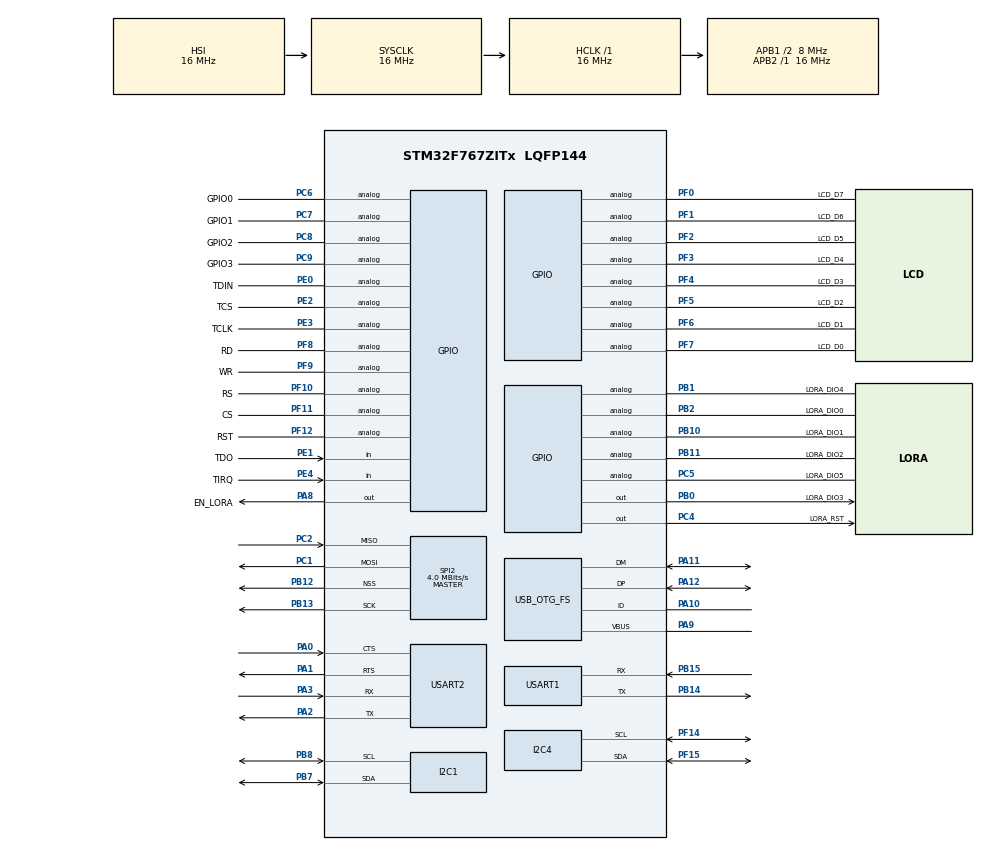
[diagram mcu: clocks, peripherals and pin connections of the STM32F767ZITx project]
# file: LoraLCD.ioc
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SPI2.VirtualType=VM_MASTER
PC6.GPIO_Label=GPIO0
PB13.Signal=SPI2_SCK
PF6.GPIO_Label=LCD_D1
PF7.Signal=GPIO_Analog
I2C4.Timing=0x2000090E
RCC.APB2TimFreq_Value=16000000
PC7.Signal=GPIO_Analog
PH1/OSC_OUT.Signal=RCC_OSC_OUT
PE1.Signal=GPIO_Input
PF10.GPIO_Label=RS
PB2.Signal=GPIO_Analog
PF1.GPIO_Label=LCD_D6
PF12.GPIO_Label=RST
PC4.GPIO_Label=LORA_RST
PB14.Mode=Asynchronous
PB1.GPIO_Label=LORA_DIO4
PE4.GPIO_Label=TIRQ
SPI2.CalculateBaudRate=4.0 MBits/s
PE2.Signal=GPIO_Analog
PA8.Signal=GPIO_Output
PF3.Signal=GPIO_Analog
Mcu.Package=LQFP144
PB1.Signal=GPIO_Analog
SPI2.Mode=SPI_MODE_MASTER
PA10.Signal=USB_OTG_FS_ID
PF14.Signal=I2C4_SCL
RCC.APB1TimFreq_Value=16000000
PB13.Mode=Full_Duplex_Master
PC2.Signal=SPI2_MISO
PC6.Signal=GPIO_Analog
PB11.GPIO_Label=LORA_DIO2
RCC.APB1CLKDivider=RCC_HCLK_DIV2
PF8.GPIO_Label=RD
PA3.Mode=Asynchronous
PA8.GPIO_Label=EN_LORA
PA9.Signal=USB_OTG_FS_VBUS
I2C1.Timing=0x2000090E
PA0/WKUP.Mode=CTS_RTS
PB10.Signal=GPIO_Analog
PB14.Signal=USART1_TX
PE1.GPIO_Label=TDO
PA1.Mode=CTS_RTS
RCC.PRESCALERUSB=RCC_USBCLKSOURCE_PLL_DIV1_5
PF4.GPIO_Label=LCD_D3
PC7.GPIO_Label=GPIO1
PA11.Signal=USB_OTG_FS_DM
ProjectManager.HeapSize=0x200
PF9.Signal=GPIO_Analog
NVIC.PriorityGroup=NVIC_PRIORITYGROUP_4
PF0.GPIO_Label=LCD_D7
PB8.Mode=I2C
PE3.Signal=GPIO_Analog
PC15/OSC32_OUT.Signal=RCC_OSC32_OUT
PF4.Signal=GPIO_Analog
PB0.Signal=GPIO_Output
PC1.Signal=SPI2_MOSI
PC1.Mode=Full_Duplex_Master
Mcu.Family=STM32F7
SPI2.VirtualNSS=VM_NSSHARD
RCC.CortexFreq_Value=16000000
RCC.SYSCLKSourceVirtual=RCC_SYSCLKSOURCE_PLLCLK
PA11.Mode=OTG/Dual_Role_Device
PA0/WKUP.Signal=USART2_CTS
PC14/OSC32_IN.Mode=LSE-External-Oscillator
PB0.GPIO_Label=LORA_DIO3
PB11.Signal=GPIO_Analog
PB15.Signal=USART1_RX
ProjectManager.StackSize=0x400
PA12.Signal=USB_OTG_FS_DP
PH0/OSC_IN.Mode=HSE-External-Oscillator
RCC.HCLKFreq_Value=16000000
PF11.GPIO_Label=CS
PF12.Signal=GPIO_Analog
RCC.AHBFreq_Value=16000000
RCC.HSE_VALUE=16000000
USART2.VirtualMode-Asynchronous=VM_ASYNC
RCC.PLLMUL=RCC_PLL_MUL9
PF7.GPIO_Label=LCD_D0
PF11.Signal=GPIO_Analog
PB7.Signal=I2C1_SDA
PE4.Signal=GPIO_Input
PH1/OSC_OUT.Mode=HSE-External-Oscillator
PF15.Mode=I2C
PB12.Mode=NSS_Signal_Hard_Output
PC14/OSC32_IN.Signal=RCC_OSC32_IN
PF5.GPIO_Label=LCD_D2
PF8.Signal=GPIO_Analog
PE0.GPIO_Label=TDIN
PF5.Signal=GPIO_Analog
SPI2.Direction=SPI_DIRECTION_2LINES
PF0.Signal=GPIO_Analog
PC5.Signal=GPIO_Analog
PF3.GPIO_Label=LCD_D4
PE2.GPIO_Label=TCS
PA3.Signal=USART2_RX
PA10.Mode=OTG/Dual_Role_Device
PC9.GPIO_Label=GPIO3
PC8.Signal=GPIO_Analog
PC4.Signal=GPIO_Output
PC2.Mode=Full_Duplex_Master
PC8.GPIO_Label=GPIO2
USART1.VirtualMode-Asynchronous=VM_ASYNC
PA9.Mode=Activate_VBUS
PF6.Signal=GPIO_Analog
ProjectManager.TargetToolchain=Makefile
PB10.GPIO_Label=LORA_DIO1
PF2.Signal=GPIO_Analog
RCC.USBFreq_Value=48000000
PF9.GPIO_Label=WR
PA1.Signal=USART2_RTS
board=NUCLEO-F767ZI
RCC.VCOOutputFreq_Value=192000000
PB15.Mode=Asynchronous
PH0/OSC_IN.Signal=RCC_OSC_IN
RCC.APB2Freq_Value=16000000
PF10.Signal=GPIO_Analog
PF14.Mode=I2C
PF15.Signal=I2C4_SDA
PF1.Signal=GPIO_Analog
Mcu.Name=STM32F767ZITx
PE0.Signal=GPIO_Analog
PA2.Signal=USART2_TX
RCC.48MHZClocksFreq_Value=24000000
RCC.SYSCLKFreq_VALUE=16000000
PA12.Mode=OTG/Dual_Role_Device
PC5.GPIO_Label=LORA_DIO5
PC15/OSC32_OUT.Mode=LSE-External-Oscillator
PB7.Mode=I2C
PB2.GPIO_Label=LORA_DIO0
RCC.HSI_VALUE=16000000
RCC.PLLQ=4
RCC.PLLM=8
RCC.PLLN=96
PA2.Mode=Asynchronous
PB8.Signal=I2C1_SCL
PE3.GPIO_Label=TCLK
PC9.Signal=GPIO_Analog
RCC.APB1Freq_Value=8000000
PB12.Signal=SPI2_NSS
PF2.GPIO_Label=LCD_D5

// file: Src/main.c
/* USER CODE BEGIN Header */
/**
 ******************************************************************************
 * @file           : main.c
 * @brief          : Main program body
 ******************************************************************************
 * @attention
 *
 * <h2><center>&copy; Copyright (c) 2020 STMicroelectronics.
 * All rights reserved.</center></h2>
 *
 * This software component is licensed by ST under BSD 3-Clause license,
 * the "License"; You may not use this file except in compliance with the
 * License. You may obtain a copy of the License at:
 *                        opensource.org/licenses/BSD-3-Clause
 *
 ******************************************************************************
 */
/* USER CODE END Header */

#include "main.h"

/* USER CODE BEGIN Includes */
#include "LCDConfigure.h"

/* USER CODE END Includes */

I2C_HandleTypeDef hi2c1;
I2C_HandleTypeDef hi2c4;

SPI_HandleTypeDef hspi2;

UART_HandleTypeDef huart1;
UART_HandleTypeDef huart2;

/* USER CODE BEGIN PV */
struct TABLE *ttable;
COLOR dotColor = (COLOR) BLUE;

/* USER CODE END PV */

void SystemClock_Config(void);
static void MX_GPIO_Init(void);
static void MX_I2C1_Init(void);
static void MX_I2C4_Init(void);
static void MX_SPI2_Init(void);
static void MX_USART1_UART_Init(void);
static void MX_USART2_UART_Init(void);
static void MX_USB_OTG_FS_USB_Init(void);

int main(void) {

	/* MCU Configuration--------------------------------------------------------*/

	/* Reset of all peripherals, Initializes the Flash interface and the Systick. */
	HAL_Init();

	/* Configure the system clock */
	SystemClock_Config();

	/* Initialize all configured peripherals */
	MX_GPIO_Init();
	MX_I2C1_Init();
	MX_I2C4_Init();
	MX_SPI2_Init();
	MX_USART1_UART_Init();
	MX_USART2_UART_Init();
	MX_USB_OTG_FS_USB_Init();
	/* USER CODE BEGIN 2 */
	ConfigureLCD7Inch();

	COLOR background = (COLOR) WHITE;
	write_screen_color(background);

	/* USER CODE END 2 */

	/* Infinite loop */
	while (1) {

	}
}

void SystemClock_Config(void) {
	RCC_OscInitTypeDef RCC_OscInitStruct = { 0 };
	RCC_ClkInitTypeDef RCC_ClkInitStruct = { 0 };
	RCC_PeriphCLKInitTypeDef PeriphClkInitStruct = { 0 };

	/** Configure LSE Drive Capability
	 */
	HAL_PWR_EnableBkUpAccess();
	/** Configure the main internal regulator output voltage
	 */
	__HAL_RCC_PWR_CLK_ENABLE();
	__HAL_PWR_VOLTAGESCALING_CONFIG(PWR_REGULATOR_VOLTAGE_SCALE3);
	/** Initializes the CPU, AHB and APB busses clocks
	 */
	RCC_OscInitStruct.OscillatorType = RCC_OSCILLATORTYPE_HSI
			| RCC_OSCILLATORTYPE_HSE;
	RCC_OscInitStruct.HSEState = RCC_HSE_ON;
	RCC_OscInitStruct.HSIState = RCC_HSI_ON;
	RCC_OscInitStruct.HSICalibrationValue = RCC_HSICALIBRATION_DEFAULT;
	RCC_OscInitStruct.PLL.PLLState = RCC_PLL_ON;
	RCC_OscInitStruct.PLL.PLLSource = RCC_PLLSOURCE_HSE;
	RCC_OscInitStruct.PLL.PLLM = 8;
	RCC_OscInitStruct.PLL.PLLN = 96;
	RCC_OscInitStruct.PLL.PLLP = RCC_PLLP_DIV2;
	RCC_OscInitStruct.PLL.PLLQ = 4;
	if (HAL_RCC_OscConfig(&RCC_OscInitStruct) != HAL_OK) {
		Error_Handler();
	}
	/** Initializes the CPU, AHB and APB busses clocks
	 */
	RCC_ClkInitStruct.ClockType = RCC_CLOCKTYPE_HCLK | RCC_CLOCKTYPE_SYSCLK
			| RCC_CLOCKTYPE_PCLK1 | RCC_CLOCKTYPE_PCLK2;
	RCC_ClkInitStruct.SYSCLKSource = RCC_SYSCLKSOURCE_HSI;
	RCC_ClkInitStruct.AHBCLKDivider = RCC_SYSCLK_DIV1;
	RCC_ClkInitStruct.APB1CLKDivider = RCC_HCLK_DIV2;
	RCC_ClkInitStruct.APB2CLKDivider = RCC_HCLK_DIV1;

	if (HAL_RCC_ClockConfig(&RCC_ClkInitStruct, FLASH_LATENCY_0) != HAL_OK) {
		Error_Handler();
	}
	PeriphClkInitStruct.PeriphClockSelection = RCC_PERIPHCLK_USART1
			| RCC_PERIPHCLK_USART2 | RCC_PERIPHCLK_I2C1 | RCC_PERIPHCLK_I2C4
			| RCC_PERIPHCLK_CLK48;
	PeriphClkInitStruct.Usart1ClockSelection = RCC_USART1CLKSOURCE_PCLK2;
	PeriphClkInitStruct.Usart2ClockSelection = RCC_USART2CLKSOURCE_PCLK1;
	PeriphClkInitStruct.I2c1ClockSelection = RCC_I2C1CLKSOURCE_PCLK1;
	PeriphClkInitStruct.I2c4ClockSelection = RCC_I2C4CLKSOURCE_PCLK1;
	PeriphClkInitStruct.Clk48ClockSelection = RCC_CLK48SOURCE_PLL;
	if (HAL_RCCEx_PeriphCLKConfig(&PeriphClkInitStruct) != HAL_OK) {
		Error_Handler();
	}
}

static void MX_I2C1_Init(void) {

	hi2c1.Instance = I2C1;
	hi2c1.Init.Timing = 0x2000090E;
	hi2c1.Init.OwnAddress1 = 0;
	hi2c1.Init.AddressingMode = I2C_ADDRESSINGMODE_7BIT;
	hi2c1.Init.DualAddressMode = I2C_DUALADDRESS_DISABLE;
	hi2c1.Init.OwnAddress2 = 0;
	hi2c1.Init.OwnAddress2Masks = I2C_OA2_NOMASK;
	hi2c1.Init.GeneralCallMode = I2C_GENERALCALL_DISABLE;
	hi2c1.Init.NoStretchMode = I2C_NOSTRETCH_DISABLE;
	if (HAL_I2C_Init(&hi2c1) != HAL_OK) {
		Error_Handler();
	}
	/** Configure Analogue filter
	 */
	if (HAL_I2CEx_ConfigAnalogFilter(&hi2c1, I2C_ANALOGFILTER_ENABLE)
			!= HAL_OK) {
		Error_Handler();
	}
	/** Configure Digital filter
	 */
	if (HAL_I2CEx_ConfigDigitalFilter(&hi2c1, 0) != HAL_OK) {
		Error_Handler();
	}

}

static void MX_I2C4_Init(void) {

	hi2c4.Instance = I2C4;
	hi2c4.Init.Timing = 0x2000090E;
	hi2c4.Init.OwnAddress1 = 0;
	hi2c4.Init.AddressingMode = I2C_ADDRESSINGMODE_7BIT;
	hi2c4.Init.DualAddressMode = I2C_DUALADDRESS_DISABLE;
	hi2c4.Init.OwnAddress2 = 0;
	hi2c4.Init.OwnAddress2Masks = I2C_OA2_NOMASK;
	hi2c4.Init.GeneralCallMode = I2C_GENERALCALL_DISABLE;
	hi2c4.Init.NoStretchMode = I2C_NOSTRETCH_DISABLE;
	if (HAL_I2C_Init(&hi2c4) != HAL_OK) {
		Error_Handler();
	}
	/** Configure Analogue filter
	 */
	if (HAL_I2CEx_ConfigAnalogFilter(&hi2c4, I2C_ANALOGFILTER_ENABLE)
			!= HAL_OK) {
		Error_Handler();
	}
	/** Configure Digital filter
	 */
	if (HAL_I2CEx_ConfigDigitalFilter(&hi2c4, 0) != HAL_OK) {
		Error_Handler();
	}

}

static void MX_SPI2_Init(void) {

	/* SPI2 parameter configuration*/
	hspi2.Instance = SPI2;
	hspi2.Init.Mode = SPI_MODE_MASTER;
	hspi2.Init.Direction = SPI_DIRECTION_2LINES;
	hspi2.Init.DataSize = SPI_DATASIZE_4BIT;
	hspi2.Init.CLKPolarity = SPI_POLARITY_LOW;
	hspi2.Init.CLKPhase = SPI_PHASE_1EDGE;
	hspi2.Init.NSS = SPI_NSS_HARD_OUTPUT;
	hspi2.Init.BaudRatePrescaler = SPI_BAUDRATEPRESCALER_2;
	hspi2.Init.FirstBit = SPI_FIRSTBIT_MSB;
	hspi2.Init.TIMode = SPI_TIMODE_DISABLE;
	hspi2.Init.CRCCalculation = SPI_CRCCALCULATION_DISABLE;
	hspi2.Init.CRCPolynomial = 7;
	hspi2.Init.CRCLength = SPI_CRC_LENGTH_DATASIZE;
	hspi2.Init.NSSPMode = SPI_NSS_PULSE_ENABLE;
	if (HAL_SPI_Init(&hspi2) != HAL_OK) {
		Error_Handler();
	}

}

static void MX_USART1_UART_Init(void) {

	huart1.Instance = USART1;
	huart1.Init.BaudRate = 115200;
	huart1.Init.WordLength = UART_WORDLENGTH_8B;
	huart1.Init.StopBits = UART_STOPBITS_1;
	huart1.Init.Parity = UART_PARITY_NONE;
	huart1.Init.Mode = UART_MODE_TX_RX;
	huart1.Init.HwFlowCtl = UART_HWCONTROL_NONE;
	huart1.Init.OverSampling = UART_OVERSAMPLING_16;
	huart1.Init.OneBitSampling = UART_ONE_BIT_SAMPLE_DISABLE;
	huart1.AdvancedInit.AdvFeatureInit = UART_ADVFEATURE_NO_INIT;
	if (HAL_UART_Init(&huart1) != HAL_OK) {
		Error_Handler();
	}

}

static void MX_USART2_UART_Init(void) {

	huart2.Instance = USART2;
	huart2.Init.BaudRate = 115200;
	huart2.Init.WordLength = UART_WORDLENGTH_8B;
	huart2.Init.StopBits = UART_STOPBITS_1;
	huart2.Init.Parity = UART_PARITY_NONE;
	huart2.Init.Mode = UART_MODE_TX_RX;
	huart2.Init.HwFlowCtl = UART_HWCONTROL_RTS_CTS;
	huart2.Init.OverSampling = UART_OVERSAMPLING_16;
	huart2.Init.OneBitSampling = UART_ONE_BIT_SAMPLE_DISABLE;
	huart2.AdvancedInit.AdvFeatureInit = UART_ADVFEATURE_NO_INIT;
	if (HAL_UART_Init(&huart2) != HAL_OK) {
		Error_Handler();
	}

}

static void MX_USB_OTG_FS_USB_Init(void) {

}

static void MX_GPIO_Init(void) {
	GPIO_InitTypeDef GPIO_InitStruct = { 0 };

	/* GPIO Ports Clock Enable */
	__HAL_RCC_GPIOE_CLK_ENABLE();
	__HAL_RCC_GPIOC_CLK_ENABLE();
	__HAL_RCC_GPIOF_CLK_ENABLE();
	__HAL_RCC_GPIOH_CLK_ENABLE();
	__HAL_RCC_GPIOA_CLK_ENABLE();
	__HAL_RCC_GPIOB_CLK_ENABLE();

	/*Configure GPIO pin Output Level */
	HAL_GPIO_WritePin(LORA_RST_GPIO_Port, LORA_RST_Pin, GPIO_PIN_RESET);

	/*Configure GPIO pin Output Level */
	HAL_GPIO_WritePin(LORA_DIO3_GPIO_Port, LORA_DIO3_Pin, GPIO_PIN_RESET);

	/*Configure GPIO pin Output Level */
	HAL_GPIO_WritePin(EN_LORA_GPIO_Port, EN_LORA_Pin, GPIO_PIN_RESET);

	/*Configure GPIO pins : TCS_Pin TCLK_Pin TDIN_Pin */
	GPIO_InitStruct.Pin = TCS_Pin | TCLK_Pin | TDIN_Pin;
	GPIO_InitStruct.Mode = GPIO_MODE_ANALOG;
	GPIO_InitStruct.Pull = GPIO_NOPULL;
	HAL_GPIO_Init(GPIOE, &GPIO_InitStruct);

	/*Configure GPIO pins : TIRQ_Pin TDO_Pin */
	GPIO_InitStruct.Pin = TIRQ_Pin | TDO_Pin;
	GPIO_InitStruct.Mode = GPIO_MODE_INPUT;
	GPIO_InitStruct.Pull = GPIO_NOPULL;
	HAL_GPIO_Init(GPIOE, &GPIO_InitStruct);

	/*Configure GPIO pins : LCD_D7_Pin LCD_D6_Pin LCD_D5_Pin LCD_D4_Pin
	 LCD_D3_Pin LCD_D2_Pin LCD_D1_Pin LCD_D0_Pin
	 RD_Pin WR_Pin RS_Pin CS_Pin
	 RST_Pin */
	GPIO_InitStruct.Pin = LCD_D7_Pin | LCD_D6_Pin | LCD_D5_Pin | LCD_D4_Pin
			| LCD_D3_Pin | LCD_D2_Pin | LCD_D1_Pin | LCD_D0_Pin | RD_Pin
			| WR_Pin | RS_Pin | CS_Pin | RST_Pin;
	GPIO_InitStruct.Mode = GPIO_MODE_ANALOG;
	GPIO_InitStruct.Pull = GPIO_NOPULL;
	HAL_GPIO_Init(GPIOF, &GPIO_InitStruct);

	/*Configure GPIO pin : LORA_RST_Pin */
	GPIO_InitStruct.Pin = LORA_RST_Pin;
	GPIO_InitStruct.Mode = GPIO_MODE_OUTPUT_PP;
	GPIO_InitStruct.Pull = GPIO_NOPULL;
	GPIO_InitStruct.Speed = GPIO_SPEED_FREQ_LOW;
	HAL_GPIO_Init(LORA_RST_GPIO_Port, &GPIO_InitStruct);

	/*Configure GPIO pins : LORA_DIO5_Pin GPIO0_Pin GPIO1_Pin GPIO2_Pin
	 GPIO3_Pin */
	GPIO_InitStruct.Pin = LORA_DIO5_Pin | GPIO0_Pin | GPIO1_Pin | GPIO2_Pin
			| GPIO3_Pin;
	GPIO_InitStruct.Mode = GPIO_MODE_ANALOG;
	GPIO_InitStruct.Pull = GPIO_NOPULL;
	HAL_GPIO_Init(GPIOC, &GPIO_InitStruct);

	/*Configure GPIO pin : LORA_DIO3_Pin */
	GPIO_InitStruct.Pin = LORA_DIO3_Pin;
	GPIO_InitStruct.Mode = GPIO_MODE_OUTPUT_PP;
	GPIO_InitStruct.Pull = GPIO_NOPULL;
	GPIO_InitStruct.Speed = GPIO_SPEED_FREQ_LOW;
	HAL_GPIO_Init(LORA_DIO3_GPIO_Port, &GPIO_InitStruct);

	/*Configure GPIO pins : LORA_DIO4_Pin LORA_DIO0_Pin LORA_DIO1_Pin LORA_DIO2_Pin */
	GPIO_InitStruct.Pin = LORA_DIO4_Pin | LORA_DIO0_Pin | LORA_DIO1_Pin
			| LORA_DIO2_Pin;
	GPIO_InitStruct.Mode = GPIO_MODE_ANALOG;
	GPIO_InitStruct.Pull = GPIO_NOPULL;
	HAL_GPIO_Init(GPIOB, &GPIO_InitStruct);

	/*Configure GPIO pin : EN_LORA_Pin */
	GPIO_InitStruct.Pin = EN_LORA_Pin;
	GPIO_InitStruct.Mode = GPIO_MODE_OUTPUT_PP;
	GPIO_InitStruct.Pull = GPIO_NOPULL;
	GPIO_InitStruct.Speed = GPIO_SPEED_FREQ_LOW;
	HAL_GPIO_Init(EN_LORA_GPIO_Port, &GPIO_InitStruct);

	/*Configure GPIO pin : PA9 */
	GPIO_InitStruct.Pin = GPIO_PIN_9;
	GPIO_InitStruct.Mode = GPIO_MODE_INPUT;
	GPIO_InitStruct.Pull = GPIO_NOPULL;
	HAL_GPIO_Init(GPIOA, &GPIO_InitStruct);

	/*Configure GPIO pins : PA10 PA11 PA12 */
	GPIO_InitStruct.Pin = GPIO_PIN_10 | GPIO_PIN_11 | GPIO_PIN_12;
	GPIO_InitStruct.Mode = GPIO_MODE_AF_PP;
	GPIO_InitStruct.Pull = GPIO_NOPULL;
	GPIO_InitStruct.Speed = GPIO_SPEED_FREQ_VERY_HIGH;
	GPIO_InitStruct.Alternate = GPIO_AF10_OTG_FS;
	HAL_GPIO_Init(GPIOA, &GPIO_InitStruct);

}

void Error_Handler(void) {
}

/************************ (C) COPYRIGHT STMicroelectronics *****END OF FILE****/
